# ATSAMG53N19 register map
Vendor: Atmel; Series: SAMG53; File version: 0
CPU: CM4 r0p1, selectable endian, MPU, FPU, 4 interrupt priority bits
Registers are 32-bit, read-write, reset 0x0 unless marked. A register's access mark holds for its fields unless they carry their own. Offsets are from the block's base; [hi:lo] are bit positions; 'fields as' and 'values as' point back to an identical list.

## I2SC0 — Inter-IC Sound Controller 0
Base 0x40000000; register names take the prefix I2SC0_
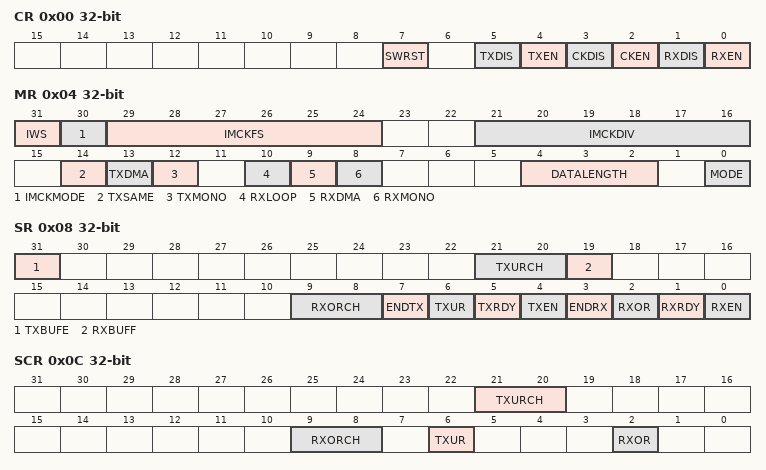
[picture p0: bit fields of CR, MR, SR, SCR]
0x00 CR wo reset not defined — Control Register
  [7] SWRST — Software Reset
  [5] TXDIS — Transmitter Disable
  [4] TXEN — Transmitter Enable
  [3] CKDIS — Clocks Disable
  [2] CKEN — Clocks Enable
  [1] RXDIS — Receiver Disable
  [0] RXEN — Receiver Enable
0x04 MR — Mode Register
  [31] IWS — I2SWS TDM Slot Width
  [30] IMCKMODE — Master Clock Mode
  [29:24] IMCKFS — Master Clock to fs Ratio
    0=M2SF16 (Sample frequency ratio set to 16); 1=M2SF32 (Sample frequency ratio set to 32); 2=M2SF48 (Sample frequency ratio set to 48); 3=M2SF64 (Sample frequency ratio set to 64); 5=M2SF96 (Sample frequency ratio set to 96); 7=M2SF128 (Sample frequency ratio set to 128); 11=M2SF192 (Sample frequency ratio set to 192); 15=M2SF256 (Sample frequency ratio set to 256); 23=M2SF384 (Sample frequency ratio set to 384); 31=M2SF512 (Sample frequency ratio set to 512); 47=M2SF768 (Sample frequency ratio set to 768); 63=M2SF1024 (Sample frequency ratio set to 1024)
  [21:16] IMCKDIV — Peripheral Clock to I2SC Master Clock Ratio
  [14] TXSAME — Transmit Data when Underrun
  [13] TXDMA — Single or Multiple PDC Channels for Transmitter
  [12] TXMONO — Transmit Mono
  [10] RXLOOP — Loop-back Test Mode
  [9] RXDMA — Single or Multiple PDC Channels for Receiver
  [8] RXMONO — Receive Mono
  [4:2] DATALENGTH — Data Word Length
    0=32_BITS (Data length is set to 32 bits); 1=24_BITS (Data length is set to 24 bits); 2=20_BITS (Data length is set to 20 bits); 3=18_BITS (Data length is set to 18 bits); 4=16_BITS (Data length is set to 16 bits); 5=16_BITS_COMPACT (Data length is set to 16-bit compact stereo. Left sample in bits 15:0 and right sample in bits 31:16 of same word.); 6=8_BITS (Data length is set to 8 bits); 7=8_BITS_COMPACT (Data length is set to 8-bit compact stereo. Left sample in bits 7:0 and right sample in bits 15:8 of the same word.)
  [0] MODE — Inter-IC Sound Controller Mode
    0=SLAVE (I2SCK and i2SWS pin inputs used as bit clock and word select/frame synchronization.); 1=MASTER (Bit clock and word select/frame synchronization generated by I2SC from MCK and output to I2SCK and I2SWS pins. MCK is output as master clock on I2SMCK if I2SC_MR.IMCKMODE is set.)
0x08 SR ro — Status Register
  [31] TXBUFE — Transmit Buffer Empty
  [21:20] TXURCH — Transmit Underrun Channel
  [19] RXBUFF — Receive Buffer Full
  [9:8] RXORCH — Receive Overrun Channel
  [7] ENDTX — End of Transmitter Transfer
  [6] TXUR — Transmit Underrun
  [5] TXRDY — Transmit Ready
  [4] TXEN — Transmitter Enabled
  [3] ENDRX — End of Receiver Transfer
  [2] RXOR — Receive Overrun
  [1] RXRDY — Receive Ready
  [0] RXEN — Receiver Enabled
0x0C SCR wo reset not defined — Status Clear Register
  [21:20] TXURCH — Transmit Underrun Per Channel Status Clear
  [9:8] RXORCH — Receive Overrun Per Channel Status Clear
  [6] TXUR — Transmit Underrun Status Clear
  [2] RXOR — Receive Overrun Status Clear
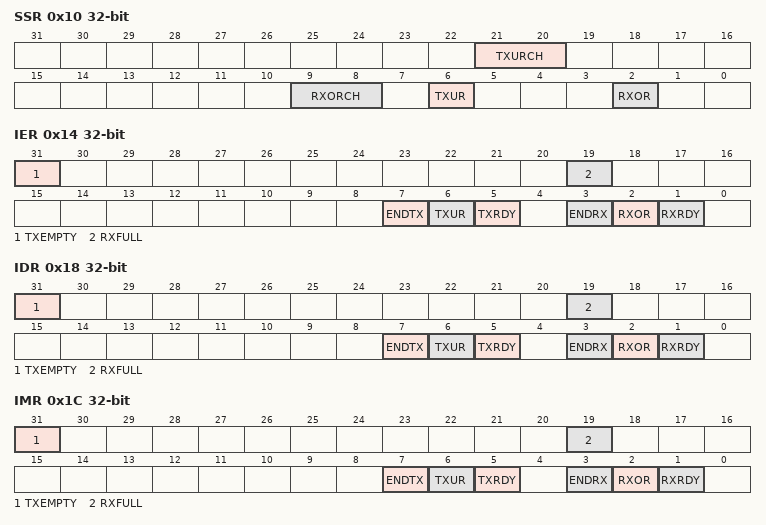
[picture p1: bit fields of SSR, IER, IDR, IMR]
0x10 SSR wo reset not defined — Status Set Register
  [21:20] TXURCH — Transmit Underrun Per Channel Status Set
  [9:8] RXORCH — Receive Overrun Per Channel Status Set
  [6] TXUR — Transmit Underrun Status Set
  [2] RXOR — Receive Overrun Status Set
0x14 IER wo reset not defined — Interrupt Enable Register
  [31] TXEMPTY — Transmit Buffer Empty Interrupt Enable
  [19] RXFULL — Receive Buffer Full Interrupt Enable
  [7] ENDTX — End of Transmission Interrupt Enable
  [6] TXUR — Transmit Underflow Interrupt Enable
  [5] TXRDY — Transmit Ready Interrupt Enable
  [3] ENDRX — End of Reception Interrupt Enable
  [2] RXOR — Receiver Overrun Interrupt Enable
  [1] RXRDY — Receiver Ready Interrupt Enable
0x18 IDR wo reset not defined — Interrupt Disable Register
  [31] TXEMPTY — Transmit Buffer Empty Interrupt Disable
  [19] RXFULL — Receive Buffer Full Interrupt Disable
  [7] ENDTX — End of Transmission Interrupt Disable
  [6] TXUR — Transmit Underflow Interrupt Disable
  [5] TXRDY — Transmit Ready Interrupt Disable
  [3] ENDRX — End of Reception Interrupt Disable
  [2] RXOR — Receiver Overrun Interrupt Disable
  [1] RXRDY — Receiver Ready Interrupt Disable
0x1C IMR ro — Interrupt Mask Register
  fields as IDR
0x20 RHR ro — Receiver Holding Register
0x24 THR wo reset not defined — Transmitter Holding Register
0x100 RPR — Receive Pointer Register
  [31:0] RXPTR
0x104 RCR — Receive Counter Register
  [15:0] RXCTR
0x108 TPR — Transmit Pointer Register
  [31:0] TXPTR — Transmit Counter Register
0x10C TCR — Transmit Counter Register
  [15:0] TXCTR
0x110 RNPR — Receive Next Pointer Register
  [31:0] RXNPTR — Receive Next Pointer
0x114 RNCR — Receive Next Counter Register
  [15:0] RXNCTR — Receive Next Counter
0x118 TNPR — Transmit Next Pointer Register
  [31:0] TXNPTR — Transmit Next Pointer
0x11C TNCR — Transmit Next Counter Register
  [15:0] TXNCTR — Transmit Counter Next
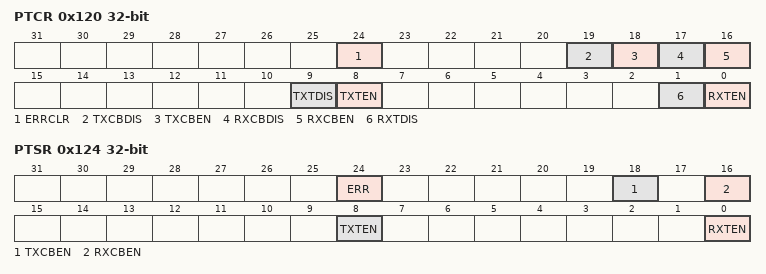
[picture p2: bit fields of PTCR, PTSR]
0x120 PTCR wo reset not defined — Transfer Control Register
  [24] ERRCLR — Transfer Bus Error Clear
  [19] TXCBDIS — Transmitter Circular Buffer Disable
  [18] TXCBEN — Transmitter Circular Buffer Enable
  [17] RXCBDIS — Receiver Circular Buffer Disable
  [16] RXCBEN — Receiver Circular Buffer Enable
  [9] TXTDIS — Transmitter Transfer Disable
  [8] TXTEN — Transmitter Transfer Enable
  [1] RXTDIS — Receiver Transfer Disable
  [0] RXTEN — Receiver Transfer Enable
0x124 PTSR ro — Transfer Status Register
  [24] ERR — Transfer Bus Error
  [18] TXCBEN — Transmitter Circular Buffer Enable
  [16] RXCBEN — Receiver Circular Buffer Enable
  [8] TXTEN — Transmitter Transfer Enable
  [0] RXTEN — Receiver Transfer Enable

## I2SC1 — Inter-IC Sound Controller 1
Base 0x40004000; register names take the prefix I2SC1_
Registers as I2SC0.

## MEM2MEM — Memory to Memory
Base 0x40028000; register names take the prefix MEM2MEM_
Registers as I2SC0, without CR, SR, SCR, SSR, IER, IDR, IMR, RHR, THR; these are added or differ:
0x00 THR — Memory to Memory Transfer Holding Register
  [31:0] THDATA — Transfer Holding Data
0x04 MR reset 0x2 — Memory to Memory Mode Register
  [1:0] TSIZE — Transfer Size
    0=T_8BIT (The buffer size is defined in byte.); 1=T_16BIT (The buffer size is defined in half-word (16-bit).); 2=T_32BIT (The buffer size is defined in word (32-bit). Default value.)
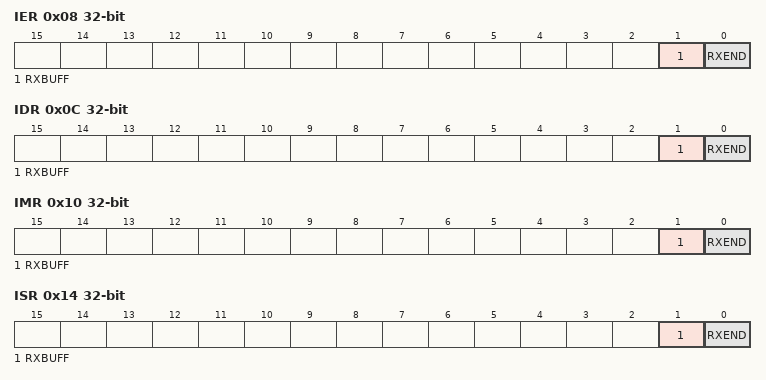
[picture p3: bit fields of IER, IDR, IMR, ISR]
0x08 IER wo reset not defined — Memory to Memory Interrupt Enable Register
  [1] RXBUFF — Buffer Full Interrupt Enable
  [0] RXEND — End of Transfer Interrupt Enable
0x0C IDR wo reset not defined — Memory to Memory Interrupt Disable Register
  [1] RXBUFF — Buffer Full Interrupt Disable
  [0] RXEND — End of Transfer Interrupt Disable
0x10 IMR ro — Memory to Memory Interrupt Mask Register
  [1] RXBUFF — Buffer Full Interrupt Mask
  [0] RXEND — End of Transfer Interrupt Mask
0x14 ISR ro reset not defined — Memory to Memory Interrupt Status Register
  [1] RXBUFF — Buffer Full
  [0] RXEND — End of Transfer

## Notices in the file
SAM Software Package License
Copyright (c) 2014, Atmel Corporation
All rights reserved.
Redistribution and use in source and binary forms, with or without
modification, are permitted provided that the following condition is met:
- Redistributions of source code must retain the above copyright notice,
this list of conditions and the disclaimer below.
Atmel's name may not be used to endorse or promote products derived from
this software without specific prior written permission.
DISCLAIMER:  THIS SOFTWARE IS PROVIDED BY ATMEL "AS IS" AND ANY EXPRESS OR
IMPLIED WARRANTIES, INCLUDING, BUT NOT LIMITED TO, THE IMPLIED WARRANTIES OF
MERCHANTABILITY, FITNESS FOR A PARTICULAR PURPOSE AND NON-INFRINGEMENT ARE
DISCLAIMED. IN NO EVENT SHALL ATMEL BE LIABLE FOR ANY DIRECT, INDIRECT,
INCIDENTAL, SPECIAL, EXEMPLARY, OR CONSEQUENTIAL DAMAGES (INCLUDING, BUT NOT
LIMITED TO, PROCUREMENT OF SUBSTITUTE GOODS OR SERVICES; LOSS OF USE, DATA,
OR PROFITS; OR BUSINESS INTERRUPTION) HOWEVER CAUSED AND ON ANY THEORY OF
LIABILITY, WHETHER IN CONTRACT, STRICT LIABILITY, OR TORT (INCLUDING
NEGLIGENCE OR OTHERWISE) ARISING IN ANY WAY OUT OF THE USE OF THIS SOFTWARE,
EVEN IF ADVISED OF THE POSSIBILITY OF SUCH DAMAGE.
